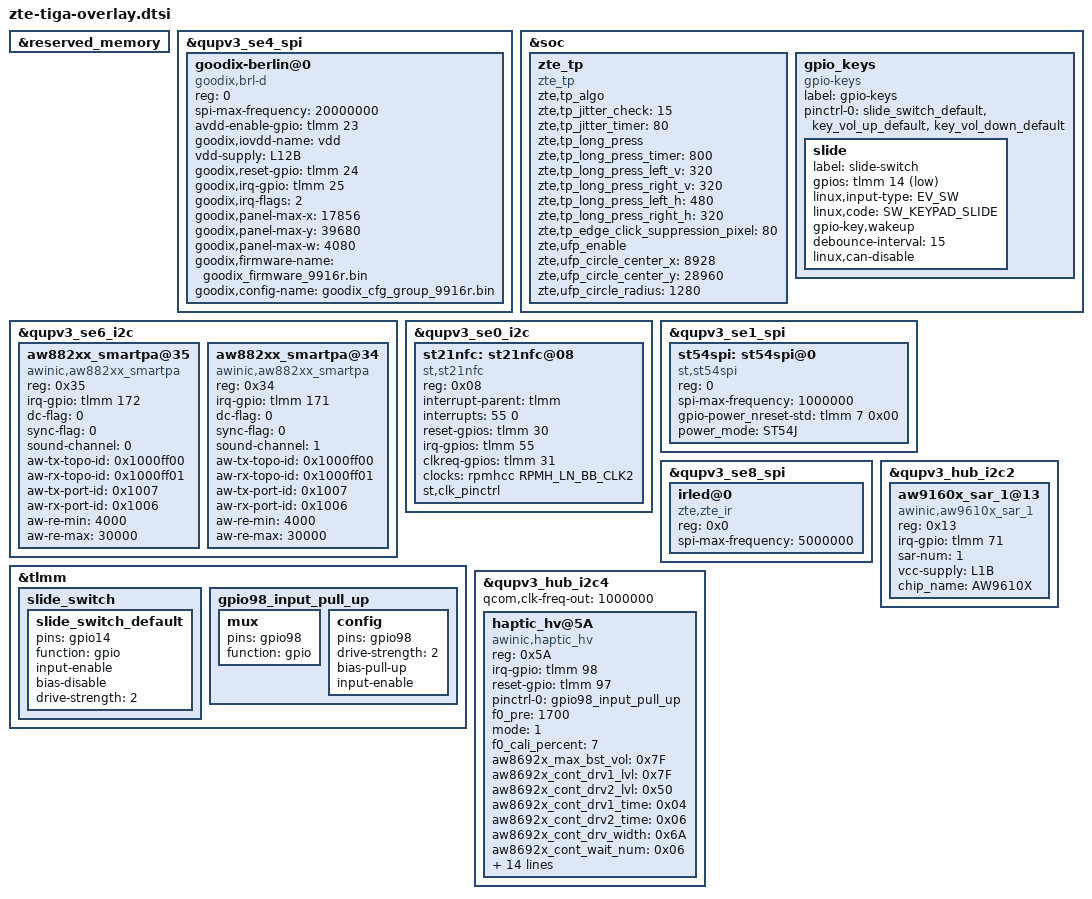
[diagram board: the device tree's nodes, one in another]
/* dtsi for tiga board (PQ82A11)*/
#include <dt-bindings/clock/qcom,rpmh.h>
#include <dt-bindings/input/input.h>
#include <dt-bindings/gpio/gpio.h>
#include "../zte-fingerprint-axon-goodix.dtsi"

&reserved_memory {
};

&qupv3_se4_spi {

	status = "ok";

	goodix-berlin@0 {
		compatible = "goodix,brl-d";
		reg = <0>;
		spi-max-frequency = <20000000>;
		avdd-enable-gpio = <&tlmm 23 0x0>;
		goodix,iovdd-name = "vdd";
		vdd-supply = <&L12B>;
		goodix,reset-gpio = <&tlmm 24 0x0>;
		goodix,irq-gpio = <&tlmm 25 0x0>;
		goodix,irq-flags = <2>; /* 1:trigger rising, 2:trigger falling;*/
		goodix,panel-max-x = <17856>;
		goodix,panel-max-y = <39680>;
		goodix,panel-max-w = <4080>;
		goodix,firmware-name = "goodix_firmware_9916r.bin";
		goodix,config-name = "goodix_cfg_group_9916r.bin";
	};
};

&soc {
	zte_tp:zte_tp {
		compatible = "zte_tp";
		zte,tp_algo;
		zte,tp_jitter_check = <15>;
		zte,tp_jitter_timer = <80>;
		zte,tp_long_press;
		zte,tp_long_press_timer = <800>;
		zte,tp_long_press_left_v = <320>;
		zte,tp_long_press_right_v = <320>;
		zte,tp_long_press_left_h = <480>; /*camera */
		zte,tp_long_press_right_h = <320>; /*charger */
		zte,tp_edge_click_suppression_pixel = <80>;
		zte,ufp_enable;
		zte,ufp_circle_center_x = <8928>;
		zte,ufp_circle_center_y = <28960>;
		zte,ufp_circle_radius = <1280>;
	};

	gpio_keys {
		compatible = "gpio-keys";
		label = "gpio-keys";
		pinctrl-names = "default";
		pinctrl-0 = <&slide_switch_default &key_vol_up_default &key_vol_down_default>;

		slide {
			label = "slide-switch";
			gpios = <&tlmm 14 GPIO_ACTIVE_LOW>;
			linux,input-type = <EV_SW>;
			linux,code = <SW_KEYPAD_SLIDE>;
			gpio-key,wakeup;
			debounce-interval = <15>;
			linux,can-disable;
		};
	};
};

&qupv3_se6_i2c {
	status = "okay";
	/* AWINIC AW882XX Smart PA */
	aw882xx_smartpa@35 {
		compatible = "awinic,aw882xx_smartpa";
		reg = <0x35>;
		irq-gpio = <&tlmm 172 0x2008>;
		dc-flag = <0>;
		sync-flag = <0>;
		sound-channel = <0>;
		aw-tx-topo-id = <0x1000ff00>;
		aw-rx-topo-id = <0x1000ff01>;
		aw-tx-port-id = <0x1007>;
		aw-rx-port-id = <0x1006>;
		aw-re-min = <4000>;
		aw-re-max= <30000>;
		/*aw-cali-mode = "none";*/
	};
	aw882xx_smartpa@34 {
		compatible = "awinic,aw882xx_smartpa";
		reg = <0x34>;
		irq-gpio = <&tlmm 171 0x2008>;
		dc-flag = <0>;
		sync-flag = <0>;
		sound-channel = <1>;
		aw-tx-topo-id = <0x1000ff00>;
		aw-rx-topo-id = <0x1000ff01>;
		aw-tx-port-id = <0x1007>;
		aw-rx-port-id = <0x1006>;
		aw-re-min = <4000>;
		aw-re-max= <30000>;
		/*aw-cali-mode = "none";*/
	};
};
	/* AWINIC AW882XX Smart PA End */

&qupv3_se0_i2c {
	 status = "ok";
	 /delete-node/ nq@28;
	 st21nfc: st21nfc@08 {
			 compatible = "st,st21nfc";
			 reg = <0x08>;
			 interrupt-parent = <&tlmm>;
			 interrupts = <55  0>;
			 reset-gpios = <&tlmm 30 0x00>;
			 irq-gpios = <&tlmm 55 0x00>;
			 // pidle-gpios = <&tlmm 48 0x00>;
			 clkreq-gpios = <&tlmm 31 0x00>;
			 clocks = <&rpmhcc RPMH_LN_BB_CLK2>;
			 clock-names = "nfc_ref_clk";
			 st,clk_pinctrl;
			 status = "ok";
	 };
};

&qupv3_se1_spi {
	 status = "ok";
	 st54spi: st54spi@0 {
			 compatible = "st,st54spi";
			 reg = <0>;
			 spi-max-frequency = <1000000>;
			 /* gpio used as SE_PWR_REQ or SE_nRESET */
			 gpio-power_nreset-std = <&tlmm 7 0x00>;

			 /* Power management mode: none, ST54H (default), ST54J */
			 power_mode = "ST54J";

			 //pinctrl-names = "qupv3_se1_spi_sleep", "qupv3_se1_spi_active";
			 //pinctrl-0 = <&qupv3_se1_spi_sleep>;
			 //pinctrl-1 = <&qupv3_se1_spi_active>;
			 status = "ok";
	 };
};

&qupv3_se8_spi {
	status = "ok";
	irled@0 {
		status = "ok";
		compatible = "zte,zte_ir";
		reg = <0x0>;
		spi-max-frequency = <5000000>;
	};
};

&tlmm {
	slide_switch {
		slide_switch_default: slide_switch_default {
			pins = "gpio14";
			function = "gpio";
			input-enable;
			bias-disable;
			drive-strength = <2>;   /* 2 mA */
		};
	};
};


/* AWINIC AW882XX Smart PA End */

/* add zte sar start */
&qupv3_hub_i2c2 {
	status = "ok";
	aw9160x_sar_1@13 {
		compatible = "awinic,aw9610x_sar_1";
		reg = <0x13>;

		irq-gpio = <&tlmm 71 0>;
		sar-num = < 1 >;
		vcc-supply = <&L1B>;

		chip_name = "AW9610X";
	};
};
/* add zte sar end */


/* add zte haptic start */
&qupv3_hub_i2c4 {
	status = "ok";
	qcom,clk-freq-out = <1000000>;
	haptic_hv@5A {
		compatible = "awinic,haptic_hv";
		reg = <0x5A>;
		irq-gpio = <&tlmm 98 0>;
		reset-gpio = <&tlmm 97 0>;
		pinctrl-names = "irq_active";
		pinctrl-0 = <&gpio98_input_pull_up>;
		f0_pre = < 1700 >;
		mode = /bits/ 8 < 1 >;
		f0_cali_percent = /bits/ 8 < 7 >;
/******************************aw8692x*******************************/
		aw8692x_max_bst_vol = /bits/ 8 < 0x7F >;
		aw8692x_cont_drv1_lvl = /bits/ 8 < 0x7F >;
		aw8692x_cont_drv2_lvl = /bits/ 8 < 0x50 >;
		aw8692x_cont_drv1_time = /bits/ 8 < 0x04 >;
		aw8692x_cont_drv2_time = /bits/ 8 < 0x06 >;
		aw8692x_cont_drv_width = /bits/ 8 < 0x6A >;
		aw8692x_cont_wait_num = /bits/ 8 < 0x06 >;
		aw8692x_cont_brk_time = /bits/ 8 < 0 >;
		aw8692x_cont_track_margin = /bits/ 8 < 0x0C >;
		aw8692x_brk_bst_md = /bits/ 8 < 0 >;
		aw8692x_cont_tset = /bits/ 8 < 0x06 >;
		aw8692x_cont_bemf_set = /bits/ 8 < 0x02 >;
		aw8692x_cont_bst_brk_gain = /bits/ 8 < 0x05 >;
		aw8692x_cont_brk_gain = /bits/ 8 < 0x08 >;
		aw8692x_duration_time = /bits/ 8 < 20 30 60 >;
		aw8692x_d2s_gain = /bits/ 8 < 0x04 >;
		aw8692x_trig_config = /bits/ 8 < 0 0 0 1 0 2 0 0
						 0 0 0 1 0 2 0 0
						 0 0 0 1 0 2 0 0 >;
		aw8692x_bst_vol_default = /bits/ 8 < 0x50 >;
		aw8692x_bst_vol_ram = /bits/ 8 < 0x50 >;
		aw8692x_bst_vol_rtp = /bits/ 8 < 0x50 >;
		/* aw8692x_is_enabled_auto_bst; */
		/* aw8692x_is_enabled_one_wire; */
	};
};

&tlmm {
	gpio98_input_pull_up: gpio98_input_pull_up {
		mux {
			 pins = "gpio98";
			 function = "gpio";
		};

		config {
			pins = "gpio98";
			drive-strength = <2>;
			bias-pull-up;
			input-enable;
		};
	};
};
/* add zte haptic start */
